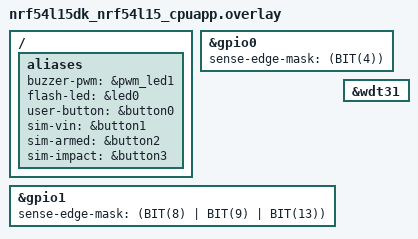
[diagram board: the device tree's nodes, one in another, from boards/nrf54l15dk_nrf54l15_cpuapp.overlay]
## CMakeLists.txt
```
# SPDX-License-Identifier: MIT

cmake_minimum_required(VERSION 3.20.0)
find_package(Zephyr REQUIRED HINTS $ENV{ZEPHYR_BASE})
project(cricket_tag)

target_sources(app PRIVATE
  src/main.c
  src/status.c
  src/adv.c
  src/gatt.c
  src/buzzer.c
  src/battery.c
  src/inputs.c
  src/modes.c
  src/dfu.c
  src/pair.c
  src/wdog.c
  src/config.c
)
target_sources_ifdef(CONFIG_CRICKET_MSP app PRIVATE src/msp.c)
target_sources_ifdef(CONFIG_CRICKET_IMPACT app PRIVATE src/impact.c)
```

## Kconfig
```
# SPDX-License-Identifier: MIT

menu "Cricket"

config CRICKET_DK_SIM
	bool "Simulate flight-controller inputs with development kit buttons"
	help
	  Button 1 toggles 5 V presence, button 2 toggles the armed state
	  reported over MSP, button 3 simulates an impact. Only for the
	  nRF54L15 DK, where the real inputs are absent.

config CRICKET_MSP
	bool "MSP link to the flight controller"
	default $(dt_alias_enabled,msp-uart)
	select SERIAL
	select UART_INTERRUPT_DRIVEN
	select PM_DEVICE
	help
	  Polls MSP_STATUS (armed) and MSP_RAW_GPS over the UART aliased
	  msp-uart while 5 V is present.

config CRICKET_IMPACT
	bool "Impact detection with the accelerometer"
	default $(dt_alias_enabled,accel0)
	select SENSOR
	select PM_DEVICE
	help
	  LIS2DH12 any-motion interrupt on INT1, high-pass filtered.
	  Needs CONFIG_LIS2DH_TRIGGER and CONFIG_LIS2DH_ACCEL_HP_FILTERS.

config CRICKET_IMPACT_MG
	int "Impact threshold, mg"
	default 8000
	range 1000 15000
	depends on CRICKET_IMPACT
	help
	  Acceleration change above this counts as an impact. Flight
	  vibration and hard landings must stay below it; tune on a drone.

config CRICKET_BUZZER_FREQ_HZ
	int "Buzzer drive frequency"
	default 4000
	help
	  CPT-1117-83 is loud across 3-8 kHz; tune by measurement.

config CRICKET_RSSI_1M
	int "Calibrated RSSI at 1 m, dBm"
	default -59
	range -128 0
	help
	  Default only: the app can change it (src/config.c).

endmenu

# The cricket-tag board has no debug UART: log over RTT (release.conf turns it off).
config USE_SEGGER_RTT
	default y if BOARD_CRICKET_TAG

source "Kconfig.zephyr"
```

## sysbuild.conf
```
# SPDX-License-Identifier: MIT
# MCUboot with two slots (swap), firmware updates over BLE through SMP (src/dfu.c).
# Signing key: firmware/build.sh passes the private key from outside the
# repository (SB_CONFIG_BOOT_SIGNATURE_KEY_FILE); see firmware/README.md.
SB_CONFIG_BOOTLOADER_MCUBOOT=y
```

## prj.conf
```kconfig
# SPDX-License-Identifier: MIT
# Cricket tag, own search mechanism (D-32). Debug configuration with UART log.

CONFIG_GPIO=y
CONFIG_PWM=y
CONFIG_ADC=y
CONFIG_HWINFO=y
CONFIG_CRC=y
CONFIG_POWEROFF=y
CONFIG_WATCHDOG=y

CONFIG_LOG=y

# Bluetooth: peripheral with two concurrent advertising sets
CONFIG_BT=y
CONFIG_BT_PERIPHERAL=y
CONFIG_BT_DEVICE_NAME="Cricket"
# The name is set from the app (src/config.c) and kept in settings
CONFIG_BT_DEVICE_NAME_DYNAMIC=y
CONFIG_BT_MAX_CONN=2
CONFIG_BT_EXT_ADV=y
CONFIG_BT_EXT_ADV_MAX_ADV_SET=2
CONFIG_BT_EXT_ADV_CODING_SELECTION=y
CONFIG_BT_CTLR_ADV_EXT=y
CONFIG_BT_CTLR_PHY_CODED=y
CONFIG_BT_USER_PHY_UPDATE=y

# Per-set TX power through the vendor HCI command, up to +8 dBm
CONFIG_BT_CTLR_TX_PWR_PLUS_8=y
CONFIG_BT_CTLR_TX_PWR_DYNAMIC_CONTROL=y

CONFIG_BT_GATT_DYNAMIC_DB=n

# Bonding with the owner's phone (src/pair.c): LE Secure Connections, Just
# Works, new pairing only in the pairing window; bonds in the storage
# partition (ZMS on RRAM).
CONFIG_BT_SMP=y
CONFIG_BT_SMP_SC_PAIR_ONLY=y
CONFIG_BT_SMP_APP_PAIRING_ACCEPT=y
CONFIG_BT_BONDABLE=y
CONFIG_BT_MAX_PAIRED=4
CONFIG_BT_KEYS_OVERWRITE_OLDEST=y
CONFIG_BT_SETTINGS=y
CONFIG_SETTINGS=y
CONFIG_ZMS=y
CONFIG_SETTINGS_ZMS=y

# Large MTU and data length for fast DFU
CONFIG_BT_L2CAP_TX_MTU=498
CONFIG_BT_BUF_ACL_RX_SIZE=502
CONFIG_BT_BUF_ACL_TX_SIZE=502
CONFIG_BT_CTLR_DATA_LENGTH_MAX=251

# Firmware update over BLE: MCUmgr SMP, image and OS groups (src/dfu.c).
# Commands are refused outside the DFU window opened by the button.
CONFIG_FLASH=y
CONFIG_FLASH_MAP=y
CONFIG_STREAM_FLASH=y
CONFIG_IMG_MANAGER=y
CONFIG_IMG_ERASE_PROGRESSIVELY=y
CONFIG_MCUBOOT_IMG_MANAGER=y
CONFIG_NET_BUF=y
CONFIG_ZCBOR=y
CONFIG_MCUMGR=y
CONFIG_MCUMGR_TRANSPORT_BT=y
CONFIG_MCUMGR_TRANSPORT_BT_PERM_RW_ENCRYPT=y
CONFIG_MCUMGR_TRANSPORT_BT_REASSEMBLY=y
CONFIG_MCUMGR_TRANSPORT_NETBUF_SIZE=1230
CONFIG_MCUMGR_GRP_IMG=y
CONFIG_MCUMGR_GRP_OS=y
CONFIG_MCUMGR_GRP_OS_MCUMGR_PARAMS=y
CONFIG_MCUMGR_MGMT_NOTIFICATION_HOOKS=y
CONFIG_MCUMGR_SMP_COMMAND_STATUS_HOOKS=y
```

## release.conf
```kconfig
# SPDX-License-Identifier: MIT
# Low-power release build: no log, console, RTT or boot banner.
# firmware/build.sh <board> -p always -- -DEXTRA_CONF_FILE=release.conf
CONFIG_LOG=n
CONFIG_CONSOLE=n
CONFIG_UART_CONSOLE=n
CONFIG_USE_SEGGER_RTT=n
CONFIG_BOOT_BANNER=n
CONFIG_ASSERT=n
```

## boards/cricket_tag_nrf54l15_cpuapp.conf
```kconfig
# Cricket tag board: no debug UART (UARTE30 is MSP); with the log on, it goes
# over SWD with RTT (default set in app/Kconfig). Measure current only with the
# release build and after a power cycle (firmware/README.md).

# LIS2DH12 for impact detection (src/impact.c): 16 g, 400 Hz low-power,
# any-motion on INT1 handled in the system work queue, HP filter on INT1.
CONFIG_LIS2DH_TRIGGER_GLOBAL_THREAD=y
CONFIG_LIS2DH_ACCEL_RANGE_16G=y
CONFIG_LIS2DH_OPER_MODE_LOW_POWER=y
CONFIG_LIS2DH_ODR_7=y
CONFIG_LIS2DH_ACCEL_HP_FILTERS=y
```

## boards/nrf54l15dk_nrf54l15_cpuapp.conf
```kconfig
# nRF54L15 DK: no flight controller, accelerometer or battery divider.
CONFIG_CRICKET_DK_SIM=y
```

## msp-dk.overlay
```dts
/*
 * SPDX-License-Identifier: MIT
 *
 * MSP on the nRF54L15 DK for testing with a real flight controller:
 * UART30, beacon TX on P0.00 -> FC RX, beacon RX on P0.01 <- FC TX, GND common.
 * Set the DK VDD to 3.3 V in Board Configurator first (default 1.8 V; FC logic is 3.3 V).
 * Build: firmware/build.sh nrf54l15dk/nrf54l15/cpuapp -p always -- -DEXTRA_DTC_OVERLAY_FILE=msp-dk.overlay
 */

/ {
	aliases {
		msp-uart = &uart30;
	};
};

&uart30 {
	status = "okay";
	current-speed = <115200>;
};
```

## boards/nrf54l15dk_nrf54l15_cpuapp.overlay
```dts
/*
 * SPDX-License-Identifier: MIT
 *
 * nRF54L15 DK stand-in for the cricket-tag board:
 *  - buzzer PWM -> LED1 (P1.10, PWM20 channel 0); a piezo can be wired there
 *  - flash LED  -> LED0
 *  - button     -> Button 0; Buttons 1-3 simulate inputs (CONFIG_CRICKET_DK_SIM)
 * No battery divider: battery voltage is not measured on the DK.
 */

/ {
	aliases {
		buzzer-pwm = &pwm_led1;
		flash-led = &led0;
		user-button = &button0;
		sim-vin = &button1;
		sim-armed = &button2;
		sim-impact = &button3;
	};
};

/* Buttons wait on GPIO SENSE, not GPIOTE event channels (lower idle current) */
&gpio0 {
	sense-edge-mask = <(BIT(4))>;
};

&gpio1 {
	sense-edge-mask = <(BIT(8) | BIT(9) | BIT(13))>;
};

/* Watchdog (src/wdog.c); disabled in the DK devicetree */
&wdt31 {
	status = "okay";
};
```

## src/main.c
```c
/* SPDX-License-Identifier: MIT */
/* Cricket tag: BLE crash beacon for drones. Own search mechanism first (D-32). */
#include "adv.h"
#include "battery.h"
#include "buzzer.h"
#include "dfu.h"
#include "modes.h"
#include "pair.h"
#include "status.h"
#include "wdog.h"

#include <zephyr/bluetooth/bluetooth.h>
#include <zephyr/kernel.h>
#include <zephyr/logging/log.h>
#include <zephyr/settings/settings.h>

LOG_MODULE_REGISTER(main, LOG_LEVEL_INF);

int main(void)
{
	int err;

	status_init();
	LOG_INF("Cricket tag, id %08x", status_id());

	err = wdog_init();
	if (err) {
		LOG_WRN("watchdog init failed (%d)", err);
	}

	err = battery_init();
	if (err) {
		LOG_WRN("battery init failed (%d)", err);
	}
	err = buzzer_init();
	if (err) {
		return err;
	}
	err = bt_enable(NULL);
	if (err) {
		LOG_ERR("Bluetooth init failed (%d)", err);
		return err;
	}
	/* bonds from the settings partition */
	err = settings_load();
	if (err) {
		LOG_WRN("settings load failed (%d)", err);
	}
	err = pair_init();
	if (err) {
		return err;
	}
	err = adv_init();
	if (err) {
		return err;
	}
	err = modes_init();
	if (err) {
		return err;
	}
	return dfu_init();
}
```

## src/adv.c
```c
/* SPDX-License-Identifier: MIT */
#include "adv.h"
#include "config.h"

#include <zephyr/bluetooth/bluetooth.h>
#include <zephyr/bluetooth/conn.h>
#include <zephyr/bluetooth/hci.h>
#include <zephyr/bluetooth/hci_vs.h>
#include <zephyr/kernel.h>
#include <zephyr/logging/log.h>
#include <zephyr/sys/byteorder.h>
#include <string.h>

LOG_MODULE_REGISTER(adv, LOG_LEVEL_INF);

enum { SET_CODED = CFG_SET_CODED, SET_1M = CFG_SET_1M, SET_COUNT = CFG_SET_COUNT };

struct adv_set {
	const char *name;
	struct bt_le_ext_adv *adv;
	uint32_t options;
	uint16_t interval_ms; /* 0: set is off */
};

static struct adv_set sets[SET_COUNT] = {
	[SET_CODED] = {
		.name = "coded",
		.options = BT_LE_ADV_OPT_CONN | BT_LE_ADV_OPT_EXT_ADV | BT_LE_ADV_OPT_CODED |
			   BT_LE_ADV_OPT_REQUIRE_S8_CODING,
	},
	[SET_1M] = {
		.name = "1m",
		.options = BT_LE_ADV_OPT_CONN, /* legacy ADV_IND, scannable */
	},
};

static struct cricket_payload payload;
static const uint8_t ad_flags = BT_LE_AD_GENERAL | BT_LE_AD_NO_BREDR;

static struct bt_data ad[] = {
	BT_DATA(BT_DATA_FLAGS, &ad_flags, sizeof(ad_flags)),
	BT_DATA(BT_DATA_MANUFACTURER_DATA, &payload, sizeof(payload)),
};

static struct bt_data sd[1]; /* device name, set from the app (config.c) */

static enum cricket_mode cur_mode = MODE_STANDBY;
static bool cur_quiet;

#define ADV_INTERVAL_MAX 0x4000 /* 10.24 s in 0.625 ms units; the host refuses more */

/* Interval for the set in the mode, ms; 0: off. Intervals per mode come from config.c. */
static uint16_t interval_for(const struct cricket_cfg *c, int set, enum cricket_mode mode,
			     bool quiet)
{
	if (mode >= CFG_MODES || (mode == MODE_ON_DRONE && quiet)) {
		return 0;
	}
	return c->interval_ms[mode][set];
}

static struct bt_le_adv_param param_for(const struct adv_set *s, uint16_t ms)
{
	/* 0.625 ms units; the +10 % window must not pass the limit (10 s intervals) */
	uint32_t min = MIN(ms * 8U / 5U, ADV_INTERVAL_MAX);
	uint32_t max = MIN(min + min / 10, ADV_INTERVAL_MAX);
	struct bt_le_adv_param p = BT_LE_ADV_PARAM_INIT(s->options, min, max, NULL);

	p.sid = s - sets;
	return p;
}

static void set_tx_power(struct adv_set *s, int8_t dbm)
{
	struct bt_hci_cp_vs_write_tx_power_level *cp;
	struct bt_hci_rp_vs_write_tx_power_level *rp;
	struct net_buf *buf, *rsp = NULL;
	uint8_t handle;
	int err;

	err = bt_hci_get_adv_handle(s->adv, &handle);
	if (err) {
		LOG_WRN("%s: no handle (%d)", s->name, err);
		return;
	}

	buf = bt_hci_cmd_alloc(K_FOREVER);
	if (!buf) {
		return;
	}
	cp = net_buf_add(buf, sizeof(*cp));
	cp->handle_type = BT_HCI_VS_LL_HANDLE_TYPE_ADV;
	cp->handle = sys_cpu_to_le16(handle);
	cp->tx_power_level = dbm;

	err = bt_hci_cmd_send_sync(BT_HCI_OP_VS_WRITE_TX_POWER_LEVEL, buf, &rsp);
	if (err) {
		LOG_WRN("%s: TX power not set (%d)", s->name, err);
		return;
	}
	rp = (void *)rsp->data;
	LOG_DBG("%s: TX power %d dBm", s->name, rp->selected_tx_power);
	net_buf_unref(rsp);
}

static void set_data(struct adv_set *s)
{
	int err;

	if (s == &sets[SET_1M]) {
		const char *name = bt_get_name();

		sd[0] = (struct bt_data)BT_DATA(BT_DATA_NAME_COMPLETE, name, strlen(name));
		err = bt_le_ext_adv_set_data(s->adv, ad, ARRAY_SIZE(ad), sd, ARRAY_SIZE(sd));
	} else {
		err = bt_le_ext_adv_set_data(s->adv, ad, ARRAY_SIZE(ad), NULL, 0);
	}
	if (err) {
		LOG_WRN("%s: set data failed (%d)", s->name, err);
	}
}

static void start(struct adv_set *s)
{
	int err;

	if (!s->interval_ms) {
		return;
	}
	err = bt_le_ext_adv_start(s->adv, BT_LE_EXT_ADV_START_DEFAULT);
	/* -ENOMEM: every connection is in use, recycled() starts the set later */
	if (err && err != -EALREADY && err != -ENOMEM) {
		LOG_WRN("%s: start failed (%d)", s->name, err);
	}
}

/*
 * A connection stops the set it came through. Restart it at once while another
 * connection is free, so that a connected phone does not hide the beacon from
 * other phones, and again once a connection object is released. On the system
 * work queue, like every other change of the sets.
 */
static void restart_fn(struct k_work *w)
{
	for (int i = 0; i < SET_COUNT; i++) {
		start(&sets[i]);
	}
}

static K_WORK_DEFINE(restart_work, restart_fn);

static void connected(struct bt_conn *conn, uint8_t err)
{
	k_work_submit(&restart_work);
}

static void recycled(void)
{
	k_work_submit(&restart_work);
}

BT_CONN_CB_DEFINE(adv_conn_cb) = {
	.connected = connected,
	.recycled = recycled,
};

int adv_init(void)
{
	int err;

	status_build(&payload);

	for (int i = 0; i < SET_COUNT; i++) {
		struct adv_set *s = &sets[i];
		struct bt_le_adv_param p = param_for(s, 1000);

		err = bt_le_ext_adv_create(&p, NULL, &s->adv);
		if (err) {
			LOG_ERR("%s: create failed (%d)", s->name, err);
			return err;
		}
		set_data(s); /* TX power is set by adv_apply() before the first start */
	}
	return 0;
}

static void disconnect(struct bt_conn *conn, void *data)
{
	int err = bt_conn_disconnect(conn, BT_HCI_ERR_REMOTE_USER_TERM_CONN);

	if (err && err != -ENOTCONN) {
		LOG_WRN("disconnect failed (%d)", err);
	}
}

void adv_apply(enum cricket_mode mode, bool quiet)
{
	struct cricket_cfg c;

	config_get(&c);
	cur_mode = mode;
	cur_quiet = quiet;

	/*
	 * Flying: stopping advertising is not enough, a phone left connected on
	 * the bench would keep the link up next to the ELRS receiver.
	 */
	if (mode == MODE_ON_DRONE && quiet) {
		bt_conn_foreach(BT_CONN_TYPE_LE, disconnect, NULL);
	}

	for (int i = 0; i < SET_COUNT; i++) {
		struct adv_set *s = &sets[i];
		uint16_t ms = interval_for(&c, i, mode, quiet);
		struct bt_le_adv_param p;
		int err;

		if (ms == s->interval_ms) {
			continue;
		}
		bt_le_ext_adv_stop(s->adv);
		s->interval_ms = ms;
		if (!ms) {
			LOG_INF("%s: off", s->name);
			continue;
		}
		p = param_for(s, ms);
		err = bt_le_ext_adv_update_param(s->adv, &p);
		if (err) {
			LOG_WRN("%s: update param failed (%d)", s->name, err);
		}
		/* after the parameters, which carry "no preference" for the power */
		set_tx_power(s, c.tx_dbm[i]);
		start(s);
		LOG_INF("%s: every %u ms", s->name, ms);
	}
}

void adv_refresh(void)
{
	status_build(&payload);
	for (int i = 0; i < SET_COUNT; i++) {
		set_data(&sets[i]);
	}
}

void adv_reload(void)
{
	if (cur_mode == MODE_SHIP) {
		return;
	}
	status_build(&payload);
	for (int i = 0; i < SET_COUNT; i++) {
		struct adv_set *s = &sets[i];

		bt_le_ext_adv_stop(s->adv);
		s->interval_ms = UINT16_MAX; /* forces adv_apply to set it up again */
		set_data(s);
	}
	adv_apply(cur_mode, cur_quiet);
}

void adv_stop_all(void)
{
	for (int i = 0; i < SET_COUNT; i++) {
		bt_le_ext_adv_stop(sets[i].adv);
		sets[i].interval_ms = 0;
	}
	cur_mode = MODE_SHIP;
}
```

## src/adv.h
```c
/* SPDX-License-Identifier: MIT */
/* Cricket advertising sets: Coded S8 (extended) and 1M (legacy), both connectable. */
#pragma once

#include <stdbool.h>
#include "status.h"

int adv_init(void);
/*
 * Set intervals for the mode; quiet on the drone (flying) silences the radio
 * (ELRS coexistence): advertising stops and connected phones are dropped.
 */
void adv_apply(enum cricket_mode mode, bool quiet);
/* Push current status into both sets' advertising data. */
void adv_refresh(void);
/* Re-read config.c settings (TX power, name, intervals) and restart the sets. */
void adv_reload(void);
void adv_stop_all(void);
```

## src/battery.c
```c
/* SPDX-License-Identifier: MIT */
#include "battery.h"

#include <zephyr/drivers/adc.h>
#include <zephyr/kernel.h>
#include <zephyr/logging/log.h>

LOG_MODULE_REGISTER(battery, LOG_LEVEL_INF);

#define USER_NODE DT_PATH(zephyr_user)

#if DT_NODE_HAS_PROP(USER_NODE, io_channels)

static const struct adc_dt_spec ch = ADC_DT_SPEC_GET(USER_NODE);

/* VBAT = V_adc * full / output; resistances from zephyr,user (vbat-full-ohms, vbat-output-ohms) */
#define DIV_FULL DT_PROP(USER_NODE, vbat_full_ohms)
#define DIV_OUT  DT_PROP(USER_NODE, vbat_output_ohms)

int battery_init(void)
{
	if (!adc_is_ready_dt(&ch)) {
		return -ENODEV;
	}
	return adc_channel_setup_dt(&ch);
}

int battery_mv(void)
{
	int16_t raw;
	int32_t mv;
	struct adc_sequence seq = {
		.buffer = &raw,
		.buffer_size = sizeof(raw),
	};

	adc_sequence_init_dt(&ch, &seq);
	if (adc_read_dt(&ch, &seq)) {
		return 0;
	}
	mv = raw;
	if (adc_raw_to_millivolts_dt(&ch, &mv)) {
		return 0;
	}
	return (int)((int64_t)mv * DIV_FULL / DIV_OUT);
}

#else

int battery_init(void)
{
	LOG_INF("no VBAT divider, battery not measured");
	return 0;
}

int battery_mv(void)
{
	return 0;
}

#endif
```

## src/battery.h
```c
/* SPDX-License-Identifier: MIT */
/* Battery voltage through the VBAT divider (io-channels of zephyr,user). */
#pragma once

int battery_init(void);
/* Battery voltage in mV, or 0 when the board has no divider (nRF54L15 DK). */
int battery_mv(void);
```

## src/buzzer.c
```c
/* SPDX-License-Identifier: MIT */
#include "buzzer.h"
#include "status.h"

#include <zephyr/drivers/gpio.h>
#include <zephyr/drivers/pwm.h>
#include <zephyr/kernel.h>
#include <zephyr/logging/log.h>

LOG_MODULE_REGISTER(buzzer, LOG_LEVEL_INF);

static const struct pwm_dt_spec pwm = PWM_DT_SPEC_GET(DT_ALIAS(buzzer_pwm));
static const struct gpio_dt_spec flash = GPIO_DT_SPEC_GET(DT_ALIAS(flash_led), gpios);

/*
 * PAM8904E gain: EN1 low = 1x, high = 3x (EN2 tied to VBAT, D-28). Optional, absent on the DK.
 * 3x on a full battery reaches the 25 Vpp limit of CPT-1117-83: use 1x while charging (firmware/README.md).
 */
#if DT_NODE_HAS_PROP(DT_PATH(zephyr_user), buz_en1_gpios)
static const struct gpio_dt_spec en1 = GPIO_DT_SPEC_GET(DT_PATH(zephyr_user), buz_en1_gpios);
#define HAS_EN1 1
#else
#define HAS_EN1 0
#endif

struct step {
	uint16_t on_ms;
	uint16_t off_ms;
};

struct pattern {
	const struct step *steps;
	uint8_t count;
	bool loud;
	bool flash;
};

#define PATTERN(name, loud_, flash_, ...)                                                    \
	static const struct step name##_steps[] = {__VA_ARGS__};                             \
	static const struct pattern name = {name##_steps, ARRAY_SIZE(name##_steps), loud_, flash_}

PATTERN(p_test, false, true, {150, 0});
PATTERN(p_ack, false, true, {60, 80}, {60, 0});
PATTERN(p_chirp, false, false, {40, 0});
PATTERN(p_alarm, true, true, {150, 100}, {150, 100}, {150, 0});
PATTERN(p_beacon, true, true, {200, 0});
PATTERN(p_find, true, true, {200, 300});
PATTERN(p_bye, false, true, {150, 100}, {300, 0});
PATTERN(p_low_batt, false, true, {400, 200}, {400, 200}, {400, 0});
PATTERN(p_no_msp, false, false, {400, 200}, {400, 0});

static const struct pattern *patterns[] = {
	[BUZZ_OFF] = NULL,     [BUZZ_TEST] = &p_test,     [BUZZ_ACK] = &p_ack,
	[BUZZ_CHIRP] = &p_chirp, [BUZZ_ALARM] = &p_alarm, [BUZZ_BEACON] = &p_beacon,
	[BUZZ_FIND] = &p_find, [BUZZ_BYE] = &p_bye,
	[BUZZ_LOW_BATT] = &p_low_batt, [BUZZ_NO_MSP] = &p_no_msp,
};

static const struct pattern *cur;
static uint8_t step;
static bool tone_on;
static int64_t find_until_ms;
static bool charging;

static void work_fn(struct k_work *w);
static K_WORK_DELAYABLE_DEFINE(work, work_fn);

static void output(bool on, bool loud, bool with_flash)
{
	uint32_t period = PWM_HZ(CONFIG_CRICKET_BUZZER_FREQ_HZ);

#if HAS_EN1
	gpio_pin_set_dt(&en1, on && loud && !charging);
#else
	ARG_UNUSED(loud);
#endif
	pwm_set_dt(&pwm, period, on ? period / 2 : 0);
	gpio_pin_set_dt(&flash, on && with_flash);
	tone_on = on;
}

static void stop(void)
{
	output(false, false, false);
	cur = NULL;
	status_update_flags(0, FLAG_BUZZING);
}

static void work_fn(struct k_work *w)
{
	const struct step *s;

	if (!cur) {
		return;
	}
	s = &cur->steps[step];

	if (!tone_on) {
		output(true, cur->loud, cur->flash);
		k_work_reschedule(&work, K_MSEC(s->on_ms));
		return;
	}

	output(false, false, false);
	step++;
	if (step == cur->count) {
		if (cur == &p_find && k_uptime_get() < find_until_ms) {
			step = 0;
		} else {
			stop();
			return;
		}
	}
	k_work_reschedule(&work, K_MSEC(s->off_ms));
}

int buzzer_init(void)
{
	if (!pwm_is_ready_dt(&pwm) || !gpio_is_ready_dt(&flash)) {
		LOG_ERR("buzzer or flash LED not ready");
		return -ENODEV;
	}
	gpio_pin_configure_dt(&flash, GPIO_OUTPUT_INACTIVE);
#if HAS_EN1
	gpio_pin_configure_dt(&en1, GPIO_OUTPUT_INACTIVE);
#endif
	output(false, false, false);
	return 0;
}

void buzzer_play(enum buzz_pattern p, uint8_t duration_s)
{
	k_work_cancel_delayable(&work);
	stop();
	if (p == BUZZ_OFF || (p == BUZZ_FIND && duration_s == 0)) {
		return;
	}
	cur = patterns[p];
	step = 0;
	find_until_ms = k_uptime_get() + duration_s * 1000LL;
	status_update_flags(FLAG_BUZZING, 0);
	k_work_reschedule(&work, K_NO_WAIT);
}

bool buzzer_active(void)
{
	return cur != NULL;
}

void buzzer_set_charging(bool c)
{
	charging = c;
}
```

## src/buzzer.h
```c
/* SPDX-License-Identifier: MIT */
/* Buzzer (PAM8904E driven by PWM) and flash LED, played as patterns. */
#pragma once

#include <stdbool.h>
#include <stdint.h>

enum buzz_pattern {
	BUZZ_OFF,
	BUZZ_TEST,   /* one short beep and flash: button press, self-test */
	BUZZ_ACK,    /* two short beeps: command accepted */
	BUZZ_CHIRP,  /* quiet short chirp: ESCALATE warning */
	BUZZ_ALARM,  /* loud burst: ALARM */
	BUZZ_BEACON, /* single loud beep: BEACON */
	BUZZ_FIND,   /* repeat beeps for the given time: app command */
	BUZZ_BYE,    /* falling double beep before SHIP */
	BUZZ_LOW_BATT, /* three long beeps: tag battery low at preflight */
	BUZZ_NO_MSP, /* two long beeps: flight controller does not answer MSP */
};

int buzzer_init(void);
/* duration_s is used by BUZZ_FIND only. A new pattern replaces the one playing. */
void buzzer_play(enum buzz_pattern pattern, uint8_t duration_s);
bool buzzer_active(void);
/* While charging VBAT reaches 4.24 V and 3x would exceed 25 Vpp on CPT-1117-83: force 1x. */
void buzzer_set_charging(bool charging);
```

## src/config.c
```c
/* SPDX-License-Identifier: MIT */
#include "config.h"
#include "adv.h"

#include <string.h>
#include <zephyr/bluetooth/att.h>
#include <zephyr/bluetooth/bluetooth.h>
#include <zephyr/kernel.h>
#include <zephyr/logging/log.h>
#include <zephyr/settings/settings.h>
#include <zephyr/sys/byteorder.h>

LOG_MODULE_REGISTER(config, LOG_LEVEL_INF);

#define CFG_STORE_VER 2

BUILD_ASSERT(CFG_NAME_MAX <= CONFIG_BT_DEVICE_NAME_MAX);
BUILD_ASSERT(sizeof(CONFIG_BT_DEVICE_NAME) - 1 <= CFG_NAME_MAX);

/* Defaults, docs/protocol.md «Наборы рекламы»: {coded, 1M} */
static const struct cricket_cfg defaults = {
	.tx_dbm = {8, 8},
	.rssi_1m = CONFIG_CRICKET_RSSI_1M,
	.interval_ms = {
		[MODE_ON_DRONE] = {1000, 1000},
		[MODE_ESCALATE] = {1000, 2000},
		[MODE_ALARM] = {1000, 2000},
		[MODE_BEACON] = {2000, 4000},
		[MODE_STANDBY] = {5000, 5000},
		[MODE_LOW_BAT] = {10000, 10000},
	},
	.preflight = 1,
};

struct cfg_store {
	uint8_t ver;
	struct cricket_cfg cfg;
};

static struct k_spinlock lock;
static struct cricket_cfg cfg = defaults;
static char new_name[CFG_NAME_MAX + 1];
static bool name_changed;
static char owner[CFG_OWNER_MAX];
static uint8_t owner_len;
static bool owner_changed;

static void apply_fn(struct k_work *w);
static K_WORK_DEFINE(apply_work, apply_fn);

static bool valid(const struct cricket_cfg *c)
{
	for (int s = 0; s < CFG_SET_COUNT; s++) {
		if (c->tx_dbm[s] < CFG_TX_MIN_DBM || c->tx_dbm[s] > CFG_TX_MAX_DBM) {
			return false;
		}
	}
	if (c->rssi_1m > 0 || c->preflight > 1) {
		return false;
	}
	for (int m = 0; m < CFG_MODES; m++) {
		bool any = false;

		for (int s = 0; s < CFG_SET_COUNT; s++) {
			uint16_t ms = c->interval_ms[m][s];

			if (ms && (ms < CFG_INTERVAL_MIN_MS || ms > CFG_INTERVAL_MAX_MS)) {
				return false;
			}
			any |= ms != 0;
		}
		/* A mode with both sets off could not be reached to undo it */
		if (!any) {
			return false;
		}
	}
	return true;
}

static int cfg_set(const char *key, size_t len, settings_read_cb read_cb, void *cb_arg)
{
	struct cfg_store st;

	if (!strcmp(key, "owner")) {
		ssize_t n = len <= CFG_OWNER_MAX ? read_cb(cb_arg, owner, len) : -EINVAL;

		owner_len = n > 0 ? n : 0;
		return 0;
	}
	if (strcmp(key, "cfg")) {
		return -ENOENT;
	}
	if (len != sizeof(st) || read_cb(cb_arg, &st, sizeof(st)) != sizeof(st) ||
	    st.ver != CFG_STORE_VER || !valid(&st.cfg)) {
		LOG_WRN("stored settings ignored, using defaults");
		return 0;
	}
	K_SPINLOCK(&lock) {
		cfg = st.cfg;
	}
	return 0;
}

SETTINGS_STATIC_HANDLER_DEFINE(cricket, "cricket", NULL, cfg_set, NULL, NULL);

void config_get(struct cricket_cfg *out)
{
	K_SPINLOCK(&lock) {
		*out = cfg;
	}
}

bool config_preflight(void)
{
	bool v;

	K_SPINLOCK(&lock) {
		v = cfg.preflight;
	}
	return v;
}

size_t config_owner(char *buf, size_t size)
{
	size_t n;

	K_SPINLOCK(&lock) {
		n = MIN(owner_len, size);
		memcpy(buf, owner, n);
	}
	return n;
}

int8_t config_rssi_1m(void)
{
	int8_t v;

	K_SPINLOCK(&lock) {
		v = cfg.rssi_1m;
	}
	return v;
}

static void apply_fn(struct k_work *w)
{
	struct cfg_store st = {.ver = CFG_STORE_VER};
	char name[CFG_NAME_MAX + 1] = "";
	char own[CFG_OWNER_MAX];
	int own_len = -1; /* unchanged */
	int err;

	K_SPINLOCK(&lock) {
		st.cfg = cfg;
		if (name_changed) {
			strcpy(name, new_name);
			name_changed = false;
		}
		if (owner_changed) {
			memcpy(own, owner, owner_len);
			own_len = owner_len;
			owner_changed = false;
		}
	}
	if (own_len > 0) {
		err = settings_save_one("cricket/owner", own, own_len);
	} else if (own_len == 0) {
		err = settings_delete("cricket/owner");
	} else {
		err = 0;
	}
	if (err) {
		LOG_WRN("owner contact not saved (%d)", err);
	}
	if (name[0]) {
		err = bt_set_name(name); /* the host stores it in settings itself */
		if (err) {
			LOG_WRN("name not set (%d)", err);
		}
	}
	err = settings_save_one("cricket/cfg", &st, sizeof(st));
	if (err) {
		LOG_WRN("settings not saved (%d)", err);
	}
	adv_reload();
	LOG_INF("settings applied");
}

static size_t put(uint8_t *buf, size_t size, size_t at, uint8_t key, const void *v, uint8_t len)
{
	if (at + 2 + len > size) {
		return at;
	}
	buf[at] = key;
	buf[at + 1] = len;
	memcpy(&buf[at + 2], v, len);
	return at + 2 + len;
}

size_t config_encode(uint8_t *buf, size_t size)
{
	struct cricket_cfg c;
	const char *name = bt_get_name();
	size_t n = 0;

	config_get(&c);
	n = put(buf, size, n, CFG_KEY_NAME, name, MIN(strlen(name), CFG_NAME_MAX));
	n = put(buf, size, n, CFG_KEY_TX_CODED, &c.tx_dbm[CFG_SET_CODED], 1);
	n = put(buf, size, n, CFG_KEY_TX_1M, &c.tx_dbm[CFG_SET_1M], 1);
	n = put(buf, size, n, CFG_KEY_RSSI_1M, &c.rssi_1m, 1);
	n = put(buf, size, n, CFG_KEY_PREFLIGHT, &c.preflight, 1);
	{
		char own[CFG_OWNER_MAX];
		size_t len = config_owner(own, sizeof(own));

		n = put(buf, size, n, CFG_KEY_OWNER, own, len);
	}
	for (int m = 0; m < CFG_MODES; m++) {
		uint8_t v[4];

		sys_put_le16(c.interval_ms[m][CFG_SET_CODED], &v[0]);
		sys_put_le16(c.interval_ms[m][CFG_SET_1M], &v[2]);
		n = put(buf, size, n, CFG_KEY_INTERVALS + m, v, sizeof(v));
	}
	return n;
}

uint8_t config_write(const uint8_t *buf, size_t len)
{
	struct cricket_cfg c;
	char name[CFG_NAME_MAX + 1] = "";
	char own[CFG_OWNER_MAX];
	int own_len = -1; /* not in this write */
	size_t at = 0;

	config_get(&c);
	while (at < len) {
		uint8_t key, vlen;
		const uint8_t *v;

		if (len - at < 2 || len - at - 2 < buf[at + 1]) {
			return BT_ATT_ERR_INVALID_ATTRIBUTE_LEN;
		}
		key = buf[at];
		vlen = buf[at + 1];
		v = &buf[at + 2];
		at += 2 + vlen;

		switch (key) {
		case CFG_KEY_NAME:
			if (vlen < 1 || vlen > CFG_NAME_MAX || memchr(v, '\0', vlen)) {
				return BT_ATT_ERR_OUT_OF_RANGE;
			}
			memcpy(name, v, vlen);
			name[vlen] = '\0';
			break;
		case CFG_KEY_OWNER:
			if (vlen > CFG_OWNER_MAX || memchr(v, '\0', vlen)) {
				return BT_ATT_ERR_OUT_OF_RANGE;
			}
			memcpy(own, v, vlen);
			own_len = vlen;
			break;
		case CFG_KEY_TX_CODED:
		case CFG_KEY_TX_1M:
		case CFG_KEY_RSSI_1M:
		case CFG_KEY_PREFLIGHT:
			if (vlen != 1) {
				return BT_ATT_ERR_INVALID_ATTRIBUTE_LEN;
			}
			if (key == CFG_KEY_RSSI_1M) {
				c.rssi_1m = (int8_t)v[0];
			} else if (key == CFG_KEY_PREFLIGHT) {
				c.preflight = v[0];
			} else {
				c.tx_dbm[key == CFG_KEY_TX_CODED ? CFG_SET_CODED : CFG_SET_1M] =
					(int8_t)v[0];
			}
			break;
		default:
			if (key < CFG_KEY_INTERVALS || key >= CFG_KEY_INTERVALS + CFG_MODES) {
				return BT_ATT_ERR_NOT_SUPPORTED;
			}
			if (vlen != 4) {
				return BT_ATT_ERR_INVALID_ATTRIBUTE_LEN;
			}
			c.interval_ms[key - CFG_KEY_INTERVALS][CFG_SET_CODED] = sys_get_le16(&v[0]);
			c.interval_ms[key - CFG_KEY_INTERVALS][CFG_SET_1M] = sys_get_le16(&v[2]);
			break;
		}
	}
	if (!valid(&c)) {
		return BT_ATT_ERR_OUT_OF_RANGE;
	}

	K_SPINLOCK(&lock) {
		cfg = c;
		if (name[0]) {
			strcpy(new_name, name);
			name_changed = true;
		}
		if (own_len >= 0) {
			memcpy(owner, own, own_len);
			owner_len = own_len;
			owner_changed = true;
		}
	}
	k_work_submit(&apply_work);
	return 0;
}

void config_reset(void)
{
	K_SPINLOCK(&lock) {
		cfg = defaults;
		strcpy(new_name, CONFIG_BT_DEVICE_NAME);
		name_changed = true;
	}
	k_work_submit(&apply_work);
}
```

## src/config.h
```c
/* SPDX-License-Identifier: MIT */
/*
 * Bluetooth settings changed from the app: device name, TX power and
 * advertising intervals per set and mode, calibrated RSSI at 1 m, preflight
 * beep, owner contact. Stored in the settings partition; docs/protocol.md
 * «Настройки».
 */
#pragma once

#include <stdbool.h>
#include <stddef.h>
#include <stdint.h>
#include <zephyr/sys/util.h>

#include "status.h"

enum { CFG_SET_CODED, CFG_SET_1M, CFG_SET_COUNT };

/* Modes whose intervals are configurable: ON_DRONE (disarmed) .. LOW_BAT */
#define CFG_MODES (MODE_LOW_BAT + 1)

struct cricket_cfg {
	int8_t tx_dbm[CFG_SET_COUNT];
	int8_t rssi_1m;
	uint16_t interval_ms[CFG_MODES][CFG_SET_COUNT]; /* 0: set off in that mode */
	uint8_t preflight; /* 1: beep the preflight check when 5 V comes */
};

/* Setting keys in the TLV encoding of the settings characteristic */
#define CFG_KEY_NAME        0x01
#define CFG_KEY_TX_CODED    0x02
#define CFG_KEY_TX_1M       0x03
#define CFG_KEY_RSSI_1M     0x04
#define CFG_KEY_OWNER       0x05 /* contact shown to whoever finds the drone */
#define CFG_KEY_PREFLIGHT   0x06
#define CFG_KEY_INTERVALS   0x10 /* + mode, value: uint16 coded ms, uint16 1M ms */

#define CFG_NAME_MAX        20
#define CFG_OWNER_MAX       64
#define CFG_TX_MIN_DBM      (-40)
#define CFG_TX_MAX_DBM      8
#define CFG_INTERVAL_MIN_MS 100
#define CFG_INTERVAL_MAX_MS 10240 /* legacy advertising limit */

void config_get(struct cricket_cfg *out);
int8_t config_rssi_1m(void);
bool config_preflight(void);
/* Owner contact, UTF-8 without a terminating zero; returns its length (0: none). */
size_t config_owner(char *buf, size_t size);

/* Encode all settings as TLV {key, len, value}; returns the length. */
size_t config_encode(uint8_t *buf, size_t size);
/*
 * Validate a TLV list from the app and apply it as a whole; nothing changes if
 * any entry is bad. Returns 0 or a BT_ATT_ERR_* code. Saving and restarting
 * advertising happen on the system work queue.
 */
uint8_t config_write(const uint8_t *buf, size_t len);
/* Back to defaults (name, power, intervals, RSSI, preflight); bonds and the owner contact are kept. */
void config_reset(void);
```

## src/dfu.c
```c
/* SPDX-License-Identifier: MIT */
#include "dfu.h"
#include "status.h"

#include <zephyr/dfu/mcuboot.h>
#include <zephyr/kernel.h>
#include <zephyr/logging/log.h>
#include <zephyr/mgmt/mcumgr/mgmt/callbacks.h>
#include <zephyr/mgmt/mcumgr/mgmt/mgmt_defines.h>

LOG_MODULE_REGISTER(dfu, LOG_LEVEL_INF);

#define DFU_WINDOW_S  300 /* after the window opens */
#define DFU_EXTEND_S  60  /* after every accepted SMP command */

static atomic_t open;
static int64_t until_ms;

static void close_fn(struct k_work *w);
static K_WORK_DELAYABLE_DEFINE(close_work, close_fn);

static void extend(int s)
{
	int64_t t = k_uptime_get() + s * 1000LL;

	if (t > until_ms) {
		until_ms = t;
		k_work_reschedule(&close_work, K_MSEC(until_ms - k_uptime_get()));
	}
}

static void close_fn(struct k_work *w)
{
	atomic_clear(&open);
	status_update_flags(0, FLAG_DFU);
	LOG_INF("DFU window closed");
}

static enum mgmt_cb_return smp_cmd(uint32_t event, enum mgmt_cb_return prev_status, int32_t *rc,
				   uint16_t *group, bool *abort_more, void *data,
				   size_t data_size)
{
	if (!atomic_get(&open)) {
		*rc = MGMT_ERR_EACCESSDENIED;
		return MGMT_CB_ERROR_RC;
	}
	extend(DFU_EXTEND_S);
	return MGMT_CB_OK;
}

static struct mgmt_callback smp_cb = {
	.callback = smp_cmd,
	.event_id = MGMT_EVT_OP_CMD_RECV,
};

int dfu_init(void)
{
	/*
	 * MCUboot runs a new image once in test mode and reverts on the next reset
	 * unless it is confirmed. Getting here means Bluetooth and the modes came
	 * up, which is the self-test.
	 */
	if (!boot_is_img_confirmed()) {
		int err = boot_write_img_confirmed();

		LOG_INF("new image confirmed (%d)", err);
	}
	mgmt_callback_register(&smp_cb);
	return 0;
}

void dfu_open(void)
{
	atomic_set(&open, 1);
	until_ms = 0;
	extend(DFU_WINDOW_S);
	status_update_flags(FLAG_DFU, 0);
	LOG_INF("DFU window open for %d s", DFU_WINDOW_S);
}
```

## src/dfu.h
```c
/* SPDX-License-Identifier: MIT */
/*
 * Firmware update over BLE (MCUmgr SMP, MCUboot). SMP commands are accepted
 * only inside a DFU window: opened by holding the button at power-up, it lasts
 * DFU_WINDOW_S and each accepted command extends it.
 */
#pragma once

int dfu_init(void);
void dfu_open(void);
```

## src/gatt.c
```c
/* SPDX-License-Identifier: MIT */
#include "gatt.h"
#include "config.h"
#include "modes.h"
#include "pair.h"
#include "status.h"

#include <zephyr/bluetooth/conn.h>
#include <zephyr/bluetooth/gatt.h>
#include <zephyr/bluetooth/uuid.h>
#include <zephyr/logging/log.h>

LOG_MODULE_REGISTER(gatt, LOG_LEVEL_INF);

#define CRICKET_UUID(last) \
	BT_UUID_128_ENCODE(0x2083eb8d, 0x7651, 0x438b, 0xb7fb, 0x75aff5da9c00 | (last))

static const struct bt_uuid_128 svc_uuid = BT_UUID_INIT_128(CRICKET_UUID(0x00));
static const struct bt_uuid_128 status_uuid = BT_UUID_INIT_128(CRICKET_UUID(0x01));
static const struct bt_uuid_128 control_uuid = BT_UUID_INIT_128(CRICKET_UUID(0x02));
static const struct bt_uuid_128 settings_uuid = BT_UUID_INIT_128(CRICKET_UUID(0x03));
static const struct bt_uuid_128 owner_uuid = BT_UUID_INIT_128(CRICKET_UUID(0x04));

#define STATUS_OFFSET offsetof(struct cricket_payload, version) /* skip Company ID */

#define OPEN_FIND_MAX_S 60 /* FIND from an unbonded phone during an alarm */

static bool notify_enabled;

static bool alarming(void)
{
	enum cricket_mode m = status_mode();

	return m == MODE_ESCALATE || m == MODE_ALARM || m == MODE_BEACON;
}

static ssize_t read_status(struct bt_conn *conn, const struct bt_gatt_attr *attr, void *buf,
			   uint16_t len, uint16_t offset)
{
	struct cricket_payload p;

	status_build(&p);
	return bt_gatt_attr_read(conn, attr, buf, len, offset, (uint8_t *)&p + STATUS_OFFSET,
				 sizeof(p) - STATUS_OFFSET);
}

static void status_ccc_changed(const struct bt_gatt_attr *attr, uint16_t value)
{
	notify_enabled = value == BT_GATT_CCC_NOTIFY;
}

static ssize_t write_control(struct bt_conn *conn, const struct bt_gatt_attr *attr,
			     const void *buf, uint16_t len, uint16_t offset, uint8_t flags)
{
	const uint8_t *cmd = buf;

	if (offset) {
		return BT_GATT_ERR(BT_ATT_ERR_INVALID_OFFSET);
	}
	if (len < 1) {
		return BT_GATT_ERR(BT_ATT_ERR_INVALID_ATTRIBUTE_LEN);
	}

	/*
	 * Commands need a bonded (encrypted) link, except FIND while the beacon is
	 * in ESCALATE, ALARM or BEACON: a helper's phone may make a crashed drone
	 * beep. The error makes Android offer pairing, which pair.c accepts only
	 * inside the pairing window.
	 */
	if (bt_conn_get_security(conn) < BT_SECURITY_L2) {
		if (cmd[0] != CRICKET_CMD_FIND || len != 2 || !alarming()) {
			return BT_GATT_ERR(BT_ATT_ERR_INSUFFICIENT_ENCRYPTION);
		}
		modes_post(EV_CMD_FIND, MIN(cmd[1], OPEN_FIND_MAX_S));
		return len;
	}

	switch (cmd[0]) {
	case CRICKET_CMD_FIND:
		if (len != 2) {
			return BT_GATT_ERR(BT_ATT_ERR_INVALID_ATTRIBUTE_LEN);
		}
		modes_post(EV_CMD_FIND, cmd[1]);
		break;
	case CRICKET_CMD_SILENCE:
		modes_post(EV_CMD_SILENCE, 0);
		break;
	case CRICKET_CMD_DFU:
		modes_post(EV_DFU, 0);
		break;
	case CRICKET_CMD_FORGET:
		pair_forget_others(bt_conn_get_dst(conn));
		break;
	case CRICKET_CMD_DEFAULTS:
		config_reset();
		break;
	default:
		LOG_WRN("unknown command 0x%02x", cmd[0]);
		return BT_GATT_ERR(BT_ATT_ERR_NOT_SUPPORTED);
	}
	return len;
}

static ssize_t read_settings(struct bt_conn *conn, const struct bt_gatt_attr *attr, void *buf,
			     uint16_t len, uint16_t offset)
{
	uint8_t v[160];
	size_t n = config_encode(v, sizeof(v));

	return bt_gatt_attr_read(conn, attr, buf, len, offset, v, n);
}

static ssize_t write_settings(struct bt_conn *conn, const struct bt_gatt_attr *attr,
			      const void *buf, uint16_t len, uint16_t offset, uint8_t flags)
{
	uint8_t err;

	if (offset) {
		return BT_GATT_ERR(BT_ATT_ERR_INVALID_OFFSET);
	}
	err = config_write(buf, len);
	if (err) {
		LOG_WRN("settings rejected (0x%02x)", err);
		return BT_GATT_ERR(err);
	}
	return len;
}

/*
 * Owner contact for whoever finds the drone: open while the beacon is lost
 * (ESCALATE, ALARM, BEACON), otherwise only over a bonded link; empty outside.
 */
static ssize_t read_owner(struct bt_conn *conn, const struct bt_gatt_attr *attr, void *buf,
			  uint16_t len, uint16_t offset)
{
	char v[CFG_OWNER_MAX];
	size_t n = 0;

	if (alarming() || bt_conn_get_security(conn) >= BT_SECURITY_L2) {
		n = config_owner(v, sizeof(v));
	}
	return bt_gatt_attr_read(conn, attr, buf, len, offset, v, n);
}

BT_GATT_SERVICE_DEFINE(cricket_svc,
	BT_GATT_PRIMARY_SERVICE(&svc_uuid),
	BT_GATT_CHARACTERISTIC(&status_uuid.uuid, BT_GATT_CHRC_READ | BT_GATT_CHRC_NOTIFY,
			       BT_GATT_PERM_READ, read_status, NULL, NULL),
	BT_GATT_CCC(status_ccc_changed, BT_GATT_PERM_READ | BT_GATT_PERM_WRITE),
	/* Encryption is checked per command in write_control */
	BT_GATT_CHARACTERISTIC(&control_uuid.uuid, BT_GATT_CHRC_WRITE,
			       BT_GATT_PERM_WRITE, NULL, write_control, NULL),
	/* Bluetooth settings (config.c): only over a bonded link */
	BT_GATT_CHARACTERISTIC(&settings_uuid.uuid, BT_GATT_CHRC_READ | BT_GATT_CHRC_WRITE,
			       BT_GATT_PERM_READ_ENCRYPT | BT_GATT_PERM_WRITE_ENCRYPT,
			       read_settings, write_settings, NULL),
	BT_GATT_CHARACTERISTIC(&owner_uuid.uuid, BT_GATT_CHRC_READ, BT_GATT_PERM_READ,
			       read_owner, NULL, NULL),
);

void gatt_notify_status(void)
{
	struct cricket_payload p;

	if (!notify_enabled) {
		return;
	}
	status_build(&p);
	bt_gatt_notify(NULL, &cricket_svc.attrs[2], (uint8_t *)&p + STATUS_OFFSET,
		       sizeof(p) - STATUS_OFFSET);
}
```

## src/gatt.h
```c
/* SPDX-License-Identifier: MIT */
/* Cricket GATT service: status (read/notify) and control (write), settings (read/write); docs/protocol.md. */
#pragma once

#define CRICKET_CMD_FIND    0x01
#define CRICKET_CMD_SILENCE 0x02
#define CRICKET_CMD_DFU     0x03
#define CRICKET_CMD_FORGET  0x04
#define CRICKET_CMD_DEFAULTS 0x05

void gatt_notify_status(void);
```
